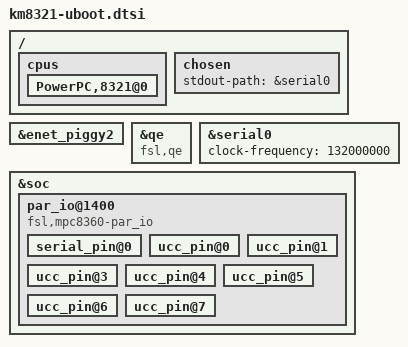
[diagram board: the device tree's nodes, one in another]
// SPDX-License-Identifier: GPL-2.0+
/*
 * Hitachi Power Grids 8321 U-Boot specific Device Tree Source parts
 *
 * Copyright (C) 2020 Heiko Schocher <hs@denx.de>
 *
 */

/ {
	cpus {
		u-boot,dm-all;
		PowerPC,8321@0 {
			u-boot,dm-all;
		};
	};

	chosen {
		stdout-path = &serial0;
	};
};

&enet_piggy2 {
	status = "okay";
};

&qe {
	compatible = "fsl,qe", "simple-bus";
};

&serial0 {
	clock-frequency = <132000000>;
	u-boot,dm-all;
};

&soc {
	u-boot,dm-all;

	par_io@1400 {
		compatible = "fsl,mpc8360-par_io";
		u-boot,dm-all;

		serial_pin@0 {
			u-boot,dm-all;
		};
		ucc_pin@0 {
			u-boot,dm-all;
		};
		ucc_pin@1 {
			u-boot,dm-all;
		};
		ucc_pin@3 {
			u-boot,dm-all;
		};
		ucc_pin@4 {
			u-boot,dm-all;
		};
		ucc_pin@5 {
			u-boot,dm-all;
		};
		ucc_pin@6 {
			u-boot,dm-all;
		};
		ucc_pin@7 {
			u-boot,dm-all;
		};
	};
};
